AUTOSAR XML (schema 4-2-2)
package /AUTOLIV/SoftwareComponents/NmIf
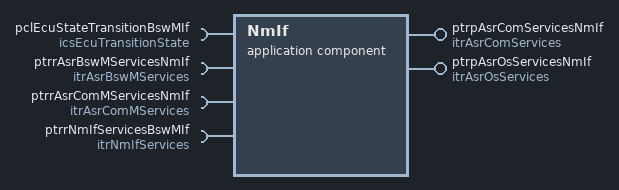
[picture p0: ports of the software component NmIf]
  application sw component type NmIf: category=BSW_Communication_Services
    require port pclEcuStateTransitionBswMIf: client-com-spec=BswM_SetEcuStateTransitionStatus, required-interface=icsEcuTransitionState  # # Architecture Element ID ARCH_SW_NmIf_pclECUStateTransitionsBswMIf # Description - The interface shall be used to set the current status of RunToLowPowerTransition flag. This interface is called every time when CAN bus is not available {timeout} and at least one frame is received on bus. # Data Flow ## Inputs: - {State of transition} - Can be one of the following values: FALSE, TRUE ## Outputs: - None # Linked Runnable - NmIf_runMainFunction # Traceability DOM_eCS_TF_P_214
    provide port ptrpAsrComServicesNmIf: provided-interface=itrAsrComServices  # # Architecture Element ID ARCH_SW_NmIf_ptrpAsrComServicesNmIf_NmIf_CbkRxAck_Airbag_01 # Description - The NmIf_CbkRxAck_Airbag_01 runnable shall be called by Autosar Com in case of reception of Airbag_01 frame. # Data Flow ## Inputs -None ## Outputs -None # Linked Runnable - NmIf_CbkRxAck_Airbag_01 #Traceability DOM_eCS_TF_P_203, DOM_eCS_TF_P_193 ------------------------------------------------------------------------------------------------------------------------------------------------ # Architecture Element ID ARCH_SW_NmIf_ptrpAsrComServicesNmIf_NmIf_CbkRxAck_Airbag_02 # Description - The NmIf_CbkRxAck_Airbag_02 runnable shall be called by Autosar Com in case of reception of Airbag_02 frame. # Data Flow ## Inputs -None ## Outputs -None # Linked Runnable - NmIf_CbkRxAck_Airbag_02 #Traceability DOM_eCS_TF_P_203, DOM_eCS_TF_P_193 ------------------------------------------------------------------------------------------------------------------------------------------------ # Architecture Element ID ARCH_SW_NmIf_ptrpAsrComServicesNmIf_NmIf_CbkRxAck_Airbag_eCS_01 # Description - The NmIf_CbkRxAck_Airbag_eCS_01 runnable shall be called by Autosar Com in case of reception of Airbag_eCS_01 frame. # Data Flow ## Inputs -None ## Outputs -None # Linked Runnable - NmIf_CbkRxAck_Airbag_eCS_01 #Traceability DOM_eCS_TF_P_203, DOM_eCS_TF_P_193 ------------------------------------------------------------------------------------------------------------------------------------------------ # Architecture Element ID ARCH_SW_NmIf_ptrpAsrComServicesNmIf_NmIf_CbkRxTOut_Airbag_01 # Description - The NmIf_CbkRxTOut_Airbag_01 runnable shall be called by Autosar Com in case of timeout on Airbag_01 frame. # Data Flow ## Inputs -None ## Outputs -None # Linked Runnable - NmIf_CbkRxTOut_Airbag_01 #Traceability DOM_eCS_TF_P_190 ------------------------------------------------------------------------------------------------------------------------------------------------ # Architecture Element ID ARCH_SW_NmIf_ptrpAsrComServicesNmIf_NmIf_CbkRxTOut_Airbag_02 # Description - The NmIf_CbkRxTOut_Airbag_02 runnable shall be called by Autosar Com in case of timeout on Airbag_02 frame. # Data Flow ## Inputs -None ## Outputs -None # Linked Runnable - NmIf_CbkRxTOut_Airbag_02 #Traceability DOM_eCS_TF_P_190 ------------------------------------------------------------------------------------------------------------------------------------------------ # Architecture Element ID ARCH_SW_NmIf_ptrpAsrComServicesNmIf_NmIf_CbkRxTOut_Airbag_eCS_01 # Description - The NmIf_CbkRxTOut_Airbag_eCS_01 runnable shall be called by Autosar Com in case of reception of Airbag_eCS_01 frame. # Data Flow ## Inputs -None ## Outputs -None # Linked Runnable - NmIf_CbkRxTOut_Airbag_eCS_01 #Traceability DOM_eCS_TF_P_190
    provide port ptrpAsrOsServicesNmIf: provided-interface=itrAsrOsServices  # # Architecture Element ID ARCH_SW_NmIf_ptrpAsrOsServicesNmIf_NmIf_runMainFunction # Description - The NmIf_runMainFunction runnable shall be called when the Os task {OsTask_Alv_Com} is executed. # Data Flow ## Inputs -None ## Outputs -None # Linked Runnable - NmIf_runMainFunction #Traceability DOM_eCS_TF_P_203
    require port ptrrAsrBswMServicesNmIf: required-interface=itrAsrBswMServices  # # Architecture Element ID ARCH_SW_NmIf_ptrrAsrBswMServicesNmIf_NmIf_runMainFunction # Description - The BswM_RequestMode runnable shall be called in the NmIf_runMainFunction runnable in order to: - Set TX PDU request port to disable tx to be able to trigger BswM rule. - Set TX PDU request port to enable tx to be able to trigger BswM rule. # Data Flow # Linked Runnable - NmIf_runMainFunction #Traceability
    require port ptrrAsrComMServicesNmIf: required-interface=itrAsrComMServices  # # Architecture Element ID ARCH_SW_NmIf_ptrrAsrComMServicesNmIf_NmIf_runMainFunction # Description - The ComM_ASR40_RequestComMode runnable shall be called in the NmIf_runMainFunction runnable in order to: - Set ComM module to silent mode to disable transmission of frames when Process Mode is requested - Set ComM module to no com mode to disable transmission and reception of frames when Bus Timeout is received - Set ComM module to full com mode to enable transmission and reception of frames when Bus ACK is received # Data Flow # Linked Runnable - NmIf_runMainFunction #Traceability DOM_eCS_TF_P_223, DOM_eCS_TF_P_224, DOM_eCS_TF_P_163, DOM_eCS_TF_P_166, DOM_eCS_TF_P_190, DOM_eCS_TF_P_193, DOM_eCS_TF_P_222
    require port ptrrNmIfServicesBswMIf: required-interface=itrNmIfServices  # # Architecture Element ID ARCH_SW_NmIf_ptrrNmIfServicesBswMIf_NmIf_runMainFunction # Description - The BswM_SetEcuStateTransitionStatus runnable shall be called when bus acknowledge is received. # Data Flow # Linked Runnable - BswM_SetEcuStateTransitionStatus # Traceability
